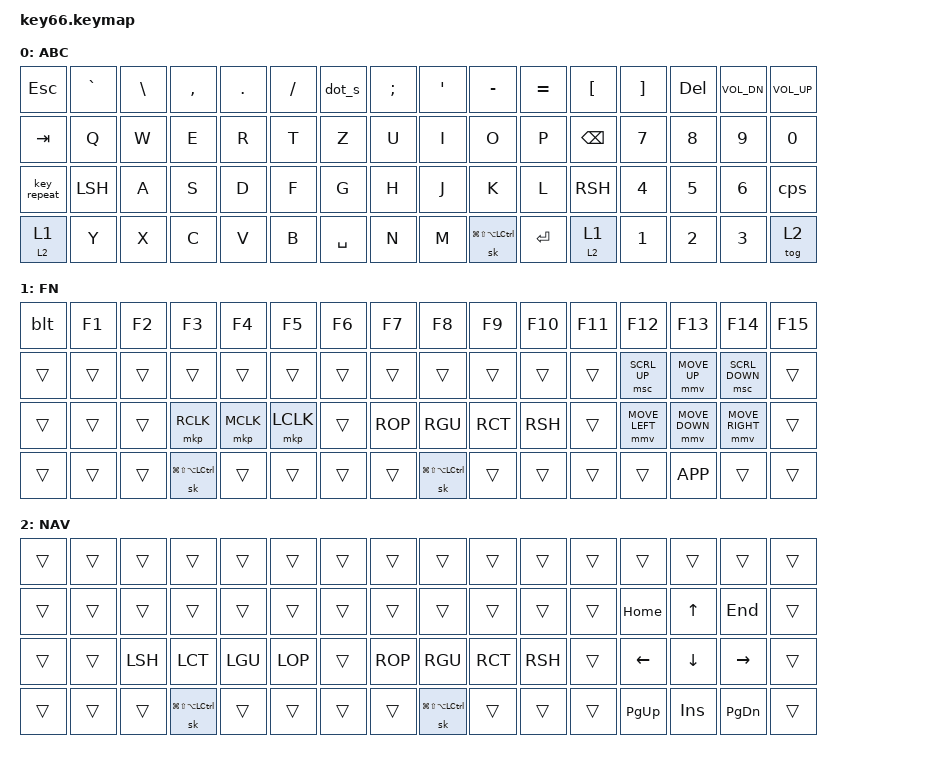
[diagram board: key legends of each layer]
#include <behaviors.dtsi>
#include <dt-bindings/zmk/keys.h>
#include <dt-bindings/zmk/bt.h>

&caps_word { continue-list = <MINUS UNDERSCORE BSPC DEL LEFT RIGHT DOT COMMA SEMI SLASH>; };
&sk { release-after-ms = <2000>; lazy; };
// &sl { release-after-ms = <1000>; };


#define xxxx &none
#define ____ &trans
#define ks(l) &ksk l l 
#define LCT ks(LCTRL)
#define LGU ks(LGUI)
#define LOP ks(LALT)
#define LSH ks(LSHFT)
#define RCT ks(RCTRL)
#define RGU ks(RGUI)
#define ROP ks(RALT)
#define RSH ks(RSHFT)
#define LEADR &sk LG(LS(LA(LCTRL)))
#define DELWRD &kp LA(BSPC)
#define REP &key_repeat

#define NAV &moto 2 1
#define RST &moto 2 0

#define ZMK_MOUSE_DEFAULT_MOVE_VAL 5000  // 600
#define ZMK_MOUSE_DEFAULT_SCRL_VAL 5000  // 10
#include <dt-bindings/zmk/pointing.h>
&mmv {
  acceleration-exponent = <1>;      // 1
  time-to-max-speed-ms = <500>;    // 40
};
&msc {
  acceleration-exponent = <1>;      // 0
  time-to-max-speed-ms = <500>;   // 500
};

/ { 
    macros {
        dot_s:  dot_space  { compatible = "zmk,behavior-macro"; #binding-cells = <0>; wait-ms = <5>; tap-ms = <15>;
            bindings = <&macro_tap &kp DOT &kp SPACE &sk LSHFT>; };
    };

    behaviors {
        ksk: kp_sk        { compatible = "zmk,behavior-hold-tap";  #binding-cells = <2>; flavor = "balanced"; tapping-term-ms = <200>; bindings = <&kp>, <&sk>; }; 
        moto: mo_tog      { compatible = "zmk,behavior-hold-tap";  #binding-cells = <2>; flavor = "balanced"; tapping-term-ms = <200>; bindings = <&mo>, <&tog>; }; 
        blt: bluetoot     { compatible = "zmk,behavior-mod-morph"; #binding-cells = <0>; bindings = <&bt BT_NXT>, <&bt BT_CLR>; mods = <MOD_RALT>; };
        cps: caps_wrd     { compatible = "zmk,behavior-mod-morph"; #binding-cells = <0>; bindings = <&caps_word>, <&kp CAPS>; mods = <MOD_RSFT>; };
    };
  
    keymap {
        compatible = "zmk,keymap";
        abc {
            display-name = "ABC";
            bindings = <
            //  1       2         3        4         5       6          7         8         9       10        11        12       13       14      15            16
                &kp ESC &kp GRAVE &kp BSLH &kp COMMA &kp DOT &kp SLASH  &dot_s    &kp SEMI  &kp SQT &kp MINUS &kp EQUAL &kp LBKT &kp RBKT &kp DEL &kp C_VOL_DN  &kp C_VOL_UP 
                &kp TAB &kp Q     &kp W    &kp E     &kp R   &kp T      &kp Z     &kp U     &kp I   &kp O     &kp P     &kp BSPC &kp N7   &kp N8  &kp N9        &kp N0 
                REP     LSH       &kp A    &kp S     &kp D   &kp F      &kp G     &kp H     &kp J   &kp K     &kp L     RSH      &kp N4   &kp N5  &kp N6        &cps 
                NAV     &kp Y     &kp X    &kp C     &kp V   &kp B      &kp SPACE &kp N     &kp M   LEADR     &kp ENTER NAV      &kp N1   &kp N2  &kp N3        &tog 2 
            >; 
        };

        fun {
            display-name = "FN";
            bindings = <
            //  1       2       3       4        5         6       7        8        9          10       11       12        13              14              15              16 
                &blt    &kp F1  &kp F2  &kp F3   &kp F4    &kp F5  &kp F6   &kp F7   &kp F8     &kp F9   &kp F10  &kp F11   &kp F12         &kp F13         &kp F14         &kp F15 
                ____    ____    ____    ____      ____     ____    ____     ____     ____       ____     ____     ____      &msc SCRL_UP    &mmv MOVE_UP    &msc SCRL_DOWN  ____ 
                ____    ____    ____ &mkp RCLK &mkp MCLK &mkp LCLK ____     ROP      RGU        RCT      RSH      ____      &mmv MOVE_LEFT  &mmv MOVE_DOWN  &mmv MOVE_RIGHT ____ 
                ____    ____    ____    LEADR     ____     ____    ____     ____     LEADR      ____     ____     ____      ____            &kp K_APP       ____            ____ 
            >; 
        };

        nav {
            display-name = "NAV";
            bindings = <
            //  1       2       3       4        5         6       7        8        9          10       11       12        13          14          15          16
                ____    ____    ____    ____      ____     ____    ____     ____     ____       ____     ____     ____      ____        ____        ____        ____ 
                ____    ____    ____    ____      ____     ____    ____     ____     ____       ____     ____     ____      &kp HOME    &kp UP      &kp END     ____ 
                ____    ____    LSH     LCT       LGU      LOP     ____     ROP      RGU        RCT      RSH      ____      &kp LEFT    &kp DOWN    &kp RIGHT   ____ 
                ____    ____    ____    LEADR     ____     ____    ____     ____     LEADR      ____     ____     ____      &kp PG_UP   &kp INS     &kp PG_DN   ____ 
            >; 
        }; 
    }; 
};
